AUTOSAR XML (schema 4-2-2)
package /AUTOLIV/SoftwareComponents/PRO
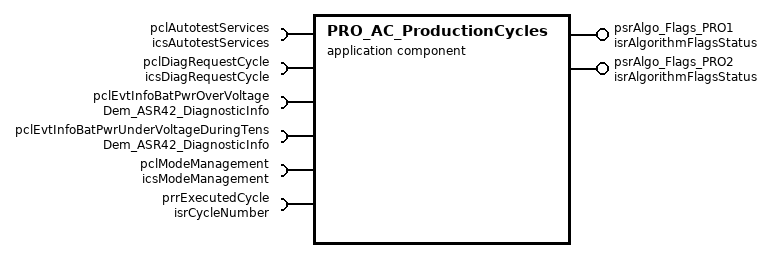
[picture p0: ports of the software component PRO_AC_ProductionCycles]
  application sw component type PRO_AC_ProductionCycles: category=SWC
    6 x require port:
      pclAutotestServices: required-com-specs=[GetTestResult, GetLastCriticalAutotestID], required-interface=icsAutotestServices
      pclDiagRequestCycle: required-com-specs=[GetDiagRequestCycle, ClearDiagRequestCycle], required-interface=icsDiagRequestCycle
      pclEvtInfoBatPwrOverVoltage: required-interface=Dem_ASR42_DiagnosticInfo
        required-com-specs:
          GetEventStatus
          GetEventFailed
          GetEventTested
          GetDTCOfEvent
          GetFaultDetectionCounter
          GetEventFreezeFrameData
          GetEventExtendedDataRecord
      pclEvtInfoBatPwrUnderVoltageDuringTens: required-interface=Dem_ASR42_DiagnosticInfo
        required-com-specs:
          GetEventStatus
          GetEventFailed
          GetEventTested
          GetDTCOfEvent
          GetFaultDetectionCounter
          GetEventFreezeFrameData
          GetEventExtendedDataRecord
      pclModeManagement: client-com-spec=CheckModeStatus, required-interface=icsModeManagement
      prrExecutedCycle: nonqueued-receiver-com-spec{data-element=u8CycleNumber, uses-end-to-end-protection=0, init-value=constant-reference=APPLINIT_KU8_CYCLE_NUMBER_NONE}, required-interface=isrCycleNumber
    provide port psrAlgo_Flags_PRO1: provided-interface=isrAlgorithmFlagsStatus
      provided-com-specs:
        data-element=b8PreActivationFlag, uses-end-to-end-protection=0, init-value=constant-reference=APPLINIT_KB8_ALGO_FLAG_FALSE
        data-element=u8TriggeringSource, uses-end-to-end-protection=1, init-value=constant-reference=APPLINIT_KU8_TRIGGERING_SOURCE_NO
        data-element=b8PreConditionsFlag, uses-end-to-end-protection=1, init-value=constant-reference=APPLINIT_KB8_ALGO_FLAG_FALSE
        data-element=b8InterruptFlag, uses-end-to-end-protection=1, init-value=constant-reference=APPLINIT_KB8_ALGO_FLAG_FALSE
        data-element=b8TriggerFlag, uses-end-to-end-protection=1, init-value=constant-reference=APPLINIT_KB8_ALGO_FLAG_FALSE
    provide port psrAlgo_Flags_PRO2: provided-interface=isrAlgorithmFlagsStatus
      provided-com-specs:
        data-element=u8TriggeringSource, uses-end-to-end-protection=1, init-value=constant-reference=APPLINIT_KU8_TRIGGERING_SOURCE_NO
        data-element=b8PreConditionsFlag, uses-end-to-end-protection=1, init-value=constant-reference=APPLINIT_KB8_ALGO_FLAG_FALSE
        data-element=b8TriggerFlag, uses-end-to-end-protection=1, init-value=constant-reference=APPLINIT_KB8_ALGO_FLAG_FALSE
        data-element=b8PreActivationFlag, uses-end-to-end-protection=1, init-value=constant-reference=APPLINIT_KB8_ALGO_FLAG_FALSE
        data-element=b8InterruptFlag, uses-end-to-end-protection=1, init-value=constant-reference=APPLINIT_KB8_ALGO_FLAG_FALSE
